# RK3399-AP register map
File version: 1
CPU: CA7 r0p1, little endian, MPU, FPU, I-cache, D-cache, VTOR, 4 interrupt priority bits, 0 interrupts
Registers are 32-bit, read-write, reset 0x0 unless marked. A register's access mark holds for its fields unless they carry their own. Offsets are from the block's base; [hi:lo] are bit positions; {n}, {i} and the like mark numbered series; 'fields as' and 'values as' point back to an identical list.

## PWM
Base 0xFF420000
{0x0+0x10*i} PWM_PWM{i}_CNT ro (i=0..3) — PWM Channel {i} Counter Register
  [31:0] CNT — Timer Counter The 32-bit indicates current value of PWM Channel {i} counter. The counter runs at the rate of PWM clock. The value ranges from 0 to (2^32-1).
{0x4+0x10*i} PWM_PWM{i}_PERIOD_HPR (i=0..3) — PWM Channel {i} Period Register/High Polarity Capture Register
  [31:0] PERIOD_HPR — Output Waveform Period/Input Waveform High Polarity Cycle If PWM is operated at the continuous mode or one-shot mode, this value defines the period of the output waveform. Note that, if the PWM is operated at the center-aligned mode, the period should be an even one, and therefore only the bit [31:1] is taken into account and bit [0] always considered as 0. If PWM is operated at the capture mode, this value indicates the effective high polarity cycles of input waveform. This value is based on the PWM clock. The value ranges from 0 to (2^32-1).
{0x8+0x10*i} PWM_PWM{i}_DUTY_LPR (i=0..3) — PWM Channel {i} Duty Register/Low Polarity Capture Register
  [31:0] DUTY_LPR — Output Waveform Duty Cycle/Input Waveform Low Polarity Cycle If PWM is operated at the continuous mode or one-shot mode, this value defines the duty cycle of the output waveform. The PWM starts the output waveform with duty cycle. Note that, if the PWM is operated at the center-aligned mode, the period should be an even one, and therefore only the [31:1] is taken into account. If PWM is operated at the capture mode, this value indicates the effective low polarity cycles of input waveform. This value is based on the PWM clock. The value ranges from 0 to (2^32-1).
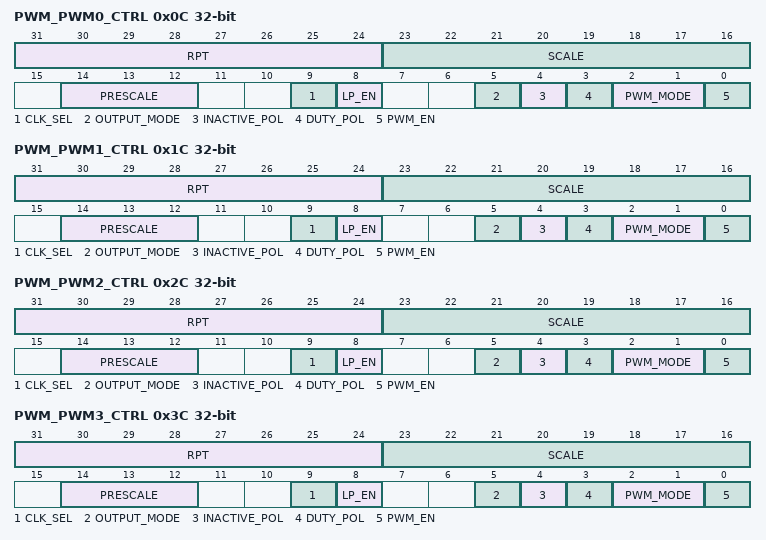
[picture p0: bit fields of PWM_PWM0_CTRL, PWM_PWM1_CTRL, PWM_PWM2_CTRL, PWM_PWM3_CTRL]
0x0C PWM_PWM0_CTRL — PWM Channel 0 Control Register
  [31:24] RPT — Repeat Counter This field defines the repeated effective periods of output waveform in one-shot mode. The value N means N+1 repeated effective periods.
  [23:16] SCALE — Scale Factor This field defines the scale factor applied to prescaled clock. The value N means the clock is divided by 2*N. If N is 0, it means that the clock is divided by 512(2*256).
  [14:12] PRESCALE — Prescale Factor This field defines the prescale factor applied to input clock. The value N means that the input clock is divided by 2^N.
  [9] CLK_SEL — Clock Source Select 0: non-scaled clock is selected as PWM clock source. It means that the prescale clock is directly used as the PWM clock source 1: scaled clock is selected as PWM clock source
  [8] LP_EN — Low Power Mode Enable 0: disabled 1: enabled When PWM channel is inactive state and Low Power Mode is enabled, the path to PWM Clock prescale module is blocked to reduce power consumption.
  [5] OUTPUT_MODE — PWM Output mode 0: left aligned mode 1: center aligned mode
  [4] INACTIVE_POL — Inactive State Output Polarity This defines the output waveform polarity when PWM channel is in inactive state. The inactive state means that PWM finishes the complete waveform in one-shot mode or PWM channel is disabled. 0: negative 1: positive
  [3] DUTY_POL — Duty Cycle Output Polarity This defines the polarity for duty cycle. PWM starts the output waveform with duty cycle. 0: negative 1: positive
  [2:1] PWM_MODE — PWM Operation Mode 00: One shot mode. PWM produces the waveform within the repeated times defined by PWMx_CTRL_rpt. 01: Continuous mode. PWM produces the waveform continuously 10: Capture mode. PWM measures the cycles of high/low polarity of input waveform. 11: reserved
  [0] PWM_EN — PWM channel enable 0: disabled 1: enabled. If the PWM is worked in the one-shot mode, this bit will be cleared at the end of operation
0x1C PWM_PWM1_CTRL — PWM Channel 1 Control Register
  [31:24] RPT — Repeat Counter This field defines the repeated effective periods of output waveform in one-shot mode. The value N means N+1 repeated effective periods.
  [23:16] SCALE — Scale Factor This field defines the scale factor applied to prescaled clock. The value N means the clock is divided by 2*N. If N is 0, it means that the clock is divided by 512(2*256).
  [14:12] PRESCALE — Prescale Factor This field defines the prescale factor applied to input clock. The value N means that the input clock is divided by 2^N.
  [9] CLK_SEL — Clock Source Select 0: non-scaled clock is selected as PWM clock source. It means that the prescale clock is directly used as the PWM clock source 1: scaled clock is selected as PWM clock source
  [8] LP_EN — Low Power Mode Enable 0: disabled 1: enabled When PWM channel is inactive state and Low Power Mode is enabled, the path to PWM Clock prescale module is blocked to reduce power consumption.
  [5] OUTPUT_MODE — PWM Output mode 0: left aligned mode 1: center aligned mode
  [4] INACTIVE_POL — Inactive State Output Polarity This defines the output waveform polarity when PWM channel is in inactive state. The inactive state means that PWM finishes the complete waveform in one-shot mode or PWM channel is disabled. 0: negative 1: positive
  [3] DUTY_POL — Duty Cycle Output Polarity This defines the polarity for duty cycle. PWM starts the output waveform with duty cycle. 0: negative 1: positive
  [2:1] PWM_MODE — PWM Operation Mode 00: One shot mode. PWM produces the waveform within the repeated times defined by PWMx_CTRL_rpt 01: Continuous mode. PWM produces the waveform continuously 10: Capture mode. PWM measures the cycles of high/low polarity of input waveform. 11: reserved
  [0] PWM_EN — PWM channel enable 0: disabled 1: enabled. If the PWM is worked in the one-shot mode, this bit will be cleared at the end of operation
0x2C PWM_PWM2_CTRL — PWM Channel 2 Control Register
  fields as PWM_PWM0_CTRL
0x3C PWM_PWM3_CTRL — PWM Channel 3 Control Register
  fields as PWM_PWM1_CTRL
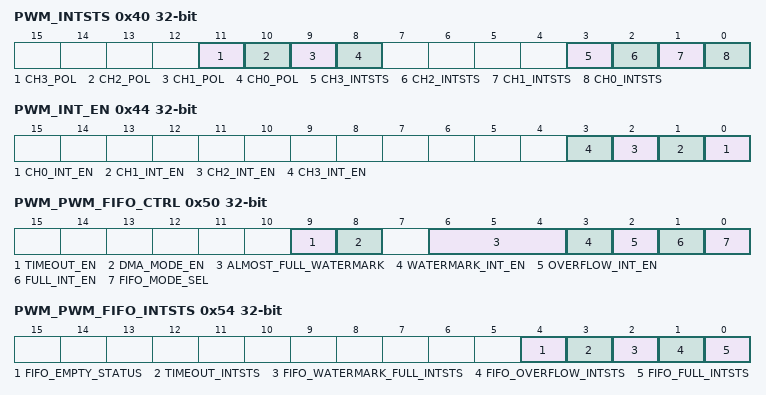
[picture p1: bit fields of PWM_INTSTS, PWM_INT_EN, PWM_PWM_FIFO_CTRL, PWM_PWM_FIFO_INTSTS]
0x40 PWM_INTSTS access per field — Interrupt Status Register
  [11] CH3_POL ro — Channel 3 Interrupt Polarity Flag This bit is used in capture mode in order to of the input waveform when interrupt is generated. When bit is 1, please refer to PWM3_PERIOD_HPR to know the effective high cycle of Channel 3 input waveform. Otherwise, please refer to PWM3_PERIOD_LPR to know the effective low cycle of Channel 3 input waveform. Write 1 to CH3_IntSts will clear this bit.
  [10] CH2_POL ro — Channel 2 Interrupt Polarity Flag This bit is used in capture mode in order to identify the transition of the input waveform when interrupt is generated. When bit is 1, please refer to PWM2_PERIOD_HPR to know the effective high cycle of Channel 2 input waveform. Otherwise, please refer to PWM2_PERIOD_LPR to know the effective low cycle of Channel 2 input waveform. Write 1 to CH2_IntSts will clear this bit.
  [9] CH1_POL ro — Channel 1 Interrupt Polarity Flag This bit is used in capture mode in order to identify the transition of the input waveform when interrupt is generated. When bit is 1, please refer to PWM1_PERIOD_HPR to know the effective high cycle of Channel 1 input waveform. Otherwise, please refer to PWM1_PERIOD_LPR to know the effective low cycle of Channel 1 input waveform. Write 1 to CH1_IntSts will clear this bit.
  [8] CH0_POL ro — Channel 0 Interrupt Polarity Flag This bit is used in capture mode in order to identify the transition of the input waveform when interrupt is generated. When bit is 1, please refer to PWM0_PERIOD_HPR to know the effective high cycle of Channel 0 input waveform. Otherwise, please refer to PWM0_PERIOD_LPR to know the effective low cycle of Channel 0 input waveform. Write 1 to CH0_IntSts will clear this bit.
  [3] CH3_INTSTS rw — Channel 3 Interrupt Status 0: Channel 3 Interrupt not generated 1: Channel 3 Interrupt generated
  [2] CH2_INTSTS rw — Channel 2 Interrupt Status 0: Channel 2 Interrupt not generated 1: Channel 2 Interrupt generated
  [1] CH1_INTSTS rw — Channel 1 Interrupt Status 0: Channel 1 Interrupt not generated 1: Channel 1 Interrupt generated
  [0] CH0_INTSTS rw — Channel 0 Raw Interrupt Status 0: Channel 0 Interrupt not generated 1: Channel 0 Interrupt generated
0x44 PWM_INT_EN — Interrupt Enable Register
  [n] CH{n}_INT_EN (n=0..3) — Channel {n} Interrupt Enable 0: Channel {n} Interrupt disabled 1: Channel {n} Interrupt enabled
0x50 PWM_PWM_FIFO_CTRL — PWM Channel 3 FIFO Mode/PWM Channel 3 FIFO Mode Control Register
  [9] TIMEOUT_EN — FIFO Timeout Enable
  [8] DMA_MODE_EN — DMA Mode Enable 1\'b1: enable 1\'b0: disable
  [6:4] ALMOST_FULL_WATERMARK — Almost Full Watermark Level
  [3] WATERMARK_INT_EN — Watermark Full Interrupt
  [2] OVERFLOW_INT_EN — FIFO Overflow Interrupt Enable When high, an interrupt asserts when the channel 3 FIFO is overflow.
  [1] FULL_INT_EN — FIFO Full Interrupt Enable When high, an interrupt asserts when the channel 3 FIFO is full.
  [0] FIFO_MODE_SEL — FIFO MODE Sel When high, PWM FIFO mode is activated
0x54 PWM_PWM_FIFO_INTSTS access per field — FIFO Interrupts Status Register
  [4] FIFO_EMPTY_STATUS ro — FIFO Empty Status This bit indicates the FIFO is empty
  [3] TIMEOUT_INTSTS rw write-1-clears — Timeout Interrupt
  [2] FIFO_WATERMARK_FULL_INTSTS rw write-1-clears — FIFO Watermark Full Interrupt Status This bit indicates the FIFO is Watermark Full
  [1] FIFO_OVERFLOW_INTSTS rw write-1-clears — FIFO Overflow Interrupt Status This bit indicates the FIFO is overflow
  [0] FIFO_FULL_INTSTS rw write-1-clears — FIFO Full Interrupt Status This bit indicates the FIFO is full
0x58 PWM_PWM_FIFO_TOUTTHR ro — FIFO Timeout Threshold Register
  [19:0] TIMEOUT_THRESHOLD — FIFO Timeout Value(unit pwmclk)
